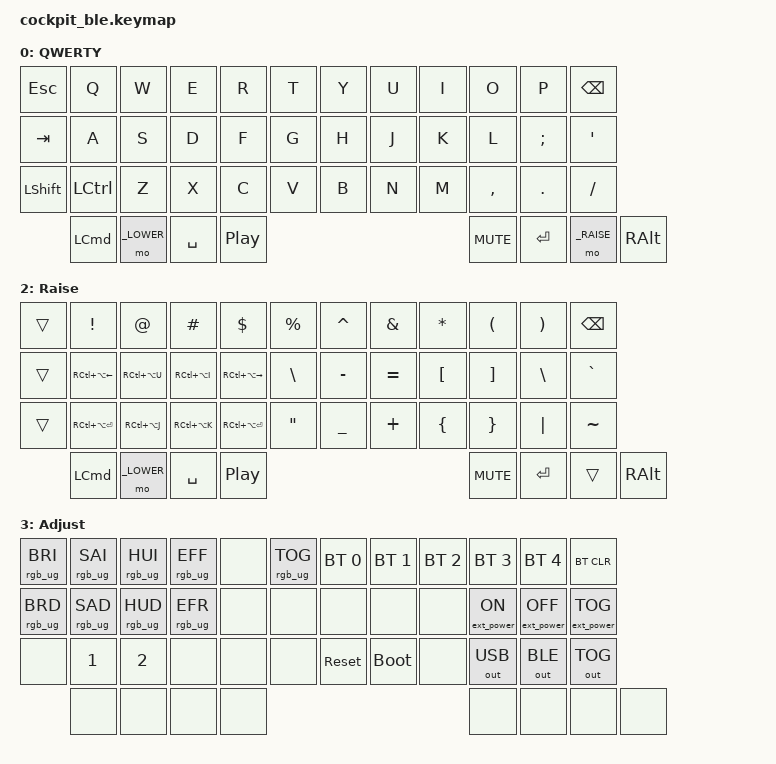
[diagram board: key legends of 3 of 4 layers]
/*
 * Copyright (c) 2023 ozkan (github.com/ozkan)
 *
 * SPDX-License-Identifier: MIT
 */

#include <behaviors.dtsi>
#include <dt-bindings/zmk/keys.h>
#include <dt-bindings/zmk/ext_power.h>
#include <dt-bindings/zmk/outputs.h>
#include <dt-bindings/zmk/bt.h>
#include <dt-bindings/zmk/rgb.h>


// Layers
#define _BASE          0
#define _LOWER         1
#define _RAISE         2
#define _ADJUST        3

// Using layer taps on thumbs, having quick tap as well helps w/ repeating space
&lt {
  quick_tap_ms = <200>;
};

&left_encoder {
     resolution = <4>; 
};
&right_encoder {
     resolution = <4>; 
};


/ {
    conditional_layers {
        compatible = "zmk,conditional-layers";
        tri_layer {
            if-layers = <_LOWER _RAISE>; // lower and raise
            then-layer = <_ADJUST>;      // adjust
        };
    };

    behaviors {
        ht: hold_tap {
            compatible = "zmk,behavior-hold-tap";
            #binding-cells = <2>;
            flavor = "tap-preferred";
            tapping-term-ms = <200>;
            quick-tap-ms = <150>;
            global-quick-tap;
            bindings = <&kp>, <&kp>;
        };
        rgb_encoder_right: rgb_encoder_right {
            compatible = "zmk,behavior-sensor-rotate";
            #sensor-binding-cells = <0>;
            bindings =  <&rgb_ug RGB_BRI>, <&rgb_ug RGB_BRD>;
        };
        rgb_encoder_left: rgb_encoder_left {
            compatible = "zmk,behavior-sensor-rotate";
            #sensor-binding-cells = <0>;
            bindings = <&rgb_ug RGB_EFF>, <&rgb_ug RGB_EFR>;
        };
    };

        combos {    
        compatible = "zmk,combos";
        
         studio_unlocking {
            timeout-ms = <50>;
            key-positions = <1 2>; 
            bindings = <&studio_unlock>; 
            layers = <_BASE>;     
        }; 

    };



    keymap {
        compatible = "zmk,keymap";
        default_layer {
       // ╭──────┬──────┬──────┬──────┬──────┬──────╮                          ╭──────┬──────┬──────┬──────┬──────┬──────╮
       // │  ESC │  Q   │  W   │  E   │  R   │  T   │                          │  Y   │  U   │  I   │  O   │  P   │ BSPC │
       // ├──────┼──────┼──────┼──────┼──────┼──────┤                          ├──────┼──────┼──────┼──────┼──────┼──────┤
       // │  TAB │  A   │  S   │  D   │  F   │  G   │                          │  H   │  J   │  K   │  L   │  ;   │  '   │
       // ├──────┼──────┼──────┼──────┼──────┼──────┤                          ├──────┼──────┼──────┼──────┼──────┼──────┤
       // │ SHFT │ CTRL │  Z   │  X   │  C   │  V   │         (ENCODERS)       │  B   │  N   │  M   │  ,   │  .   │  /   │
       // ╰──────┴──────┴──────┼──────┼──────┼──────┴─╮ ╭────────╮╭────────╮ ╭─┴──────┼──────┼──────┼──────┴──────┴──────╯
       //                      │  CMD │LOWER │ SPACE  │ │  PLAY  ││  MUTE  │ │  RET   │RAISE │ RALT │
       //                      ╰──────┴──────┴────────╯ ╰────────╯╰────────╯ ╰────────┴──────┴──────╯
            display-name = "QWERTY";
            bindings = <
                &kp ESC      &kp Q           &kp W   &kp E   &kp R   &kp T             &kp Y &kp U  &kp I    &kp O           &kp P           &kp BSPC
                &kp TAB      &kp A           &kp S   &kp D   &kp F   &kp G             &kp H &kp J  &kp K    &kp L           &kp SEMI        &kp SQT
                &kp LSHFT    &kp LCTRL       &kp Z   &kp X   &kp C   &kp V             &kp B &kp N  &kp M    &kp COMMA       &kp DOT         &kp FSLH
                                    &kp LCMD      &mo _LOWER      &kp SPACE         &kp C_PLAY_PAUSE  &kp C_MUTE       &kp RET     &mo _RAISE      &kp RALT
                                                         
            >;
            sensor-bindings = <&inc_dec_kp C_VOL_UP C_VOL_DN &inc_dec_kp RIGHT LEFT>;
        };

        lower_layer {
        // ╭──────┬──────┬──────┬──────┬──────┬──────╮                          ╭──────┬──────┬──────┬──────┬──────┬──────╮
        // │ ESC  │  1   │  2   │  3   │  4   │  5   │                          │  6   │  7   │  8   │  9   │  0   │ BSPC │
        // ├──────┼──────┼──────┼──────┼──────┼──────┤                          ├──────┼──────┼──────┼──────┼──────┼──────┤
        // │ TAB  │ C-UP │C-LEFT│C-RGHT│ LEFT │ RGHT │                          │ LEFT │ DOWN │  UP  │ RGHT │      │      │
        // ├──────┼──────┼──────┼──────┼──────┼──────┤                          ├──────┼──────┼──────┼──────┼──────┼──────┤
        // │ SHFT │  ~   │ NEXT │VOL_DN│VOL_UP│ PLAY │                          │ HOME │ END  │ PGUP │ PGDN │      │      │
        // ╰──────┴──────┴──────┼──────┼──────┼──────┴─╮ ╭────────╮╭────────╮ ╭─┴──────┼──────┼──────┼──────┴──────┴──────╯
        //                      │  CMD │      │  ALT   │ │        ││        │ │  RET   │RAISE │ RALT │
        //                      ╰──────┴──────┴────────╯ ╰────────╯╰────────╯ ╰────────┴──────┴──────╯
            display-name = "Lower";        
            bindings = <
                &kp ESC    &kp N1        &kp N2          &kp N3          &kp N4          &kp N5              &kp N6    &kp N7    &kp N8    &kp N9     &kp N0     &kp BSPC
                &kp TAB    &kp RC(UP)    &kp RC(LEFT)    &kp RC(RIGHT)   &kp LEFT        &kp RIGHT           &kp LEFT  &kp DOWN  &kp UP    &kp RIGHT  &trans     &trans
                &kp LSHFT  &kp TILDE     &kp C_NEXT      &kp C_VOL_DN    &kp C_VOL_UP    &kp C_PLAY_PAUSE    &kp HOME  &kp END   &kp PG_UP &kp PG_DN  &trans     &trans
                                          &kp LCMD      &trans      &kp LALT                     &kp RET     &mo _RAISE     &kp RALT
            >;
            
            
        };
        
        raise_layer {
        // ╭──────┬──────┬──────┬──────┬──────┬──────╮                          ╭──────┬──────┬──────┬──────┬──────┬──────╮
        // │      │  !   │  @   │  #   │  $   │  %   │                          │  ^   │  &   │  *   │  (   │  )   │ BSPC │
        // ├──────┼──────┼──────┼──────┼──────┼──────┤                          ├──────┼──────┼──────┼──────┼──────┼──────┤
        // │      │ RECT │ RECT │ RECT │ RECT │  \   │                          │  -   │  =   │  [   │  ]   │  \   │  `   │
        // ├──────┼──────┼──────┼──────┼──────┼──────┤                          ├──────┼──────┼──────┼──────┼──────┼──────┤
        // │      │ RECT │ RECT │ RECT │ RECT │  "   │                          │  _   │  +   │  {   │  }   │  |   │  ~   │
        // ╰──────┴──────┴──────┼──────┼──────┼──────┴─╮ ╭────────╮╭────────╮ ╭─┴──────┼──────┼──────┼──────┴──────┴──────╯
        //                      │  CMD │LOWER │ SPACE  │ │  PLAY  ││  MUTE  │ │  RET   │      │ RALT │
        //                      ╰──────┴──────┴────────╯ ╰────────╯╰────────╯ ╰────────┴──────┴──────╯
            display-name = "Raise";
            bindings = <
                &trans &kp EXCL              &kp AT          &kp HASH        &kp DLLR                &kp PRCNT  &kp CARET  &kp AMPS   &kp ASTRK   &kp LPAR    &kp RPAR   &kp BSPC
                &trans &kp RC(LA(LEFT))      &kp RC(LA(U))   &kp RC(LA(I))   &kp RC(LA(RIGHT))       &kp BSLH   &kp MINUS  &kp EQUAL  &kp LBKT    &kp RBKT    &kp BSLH   &kp GRAVE
                &trans &kp RC(LA(RET))       &kp RC(LA(J))   &kp RC(LA(K))   &kp RC(LA(RET))         &kp DQT    &kp UNDER  &kp PLUS   &kp LBRC    &kp RBRC    &kp PIPE   &kp TILDE
                                         &kp LCMD  &mo _LOWER &kp SPACE          &kp C_PLAY_PAUSE  &kp C_MUTE       &kp RET  &trans   &kp RALT
            >;

        };

        adjust_layer {
        // ╭──────┬──────┬──────┬──────┬──────┬──────╮                          ╭──────┬──────┬──────┬──────┬──────┬──────╮
        // │ BRI+ │ SAT+ │ HUE+ │ ANI+ │      │ TOG  │                          │  BT1 │ BT2  │ BT3  │ BT4  │ BT5  │BT_CLR│
        // ├──────┼──────┼──────┼──────┼──────┼──────┤                          ├──────┼──────┼──────┼──────┼──────┼──────┤
        // │ BRI- │ SAT- │ HUE- │ ANI- │      │      │                          │      │      │      │EP_ON │EP_OFF│EP_TOG│
        // ├──────┼──────┼──────┼──────┼──────┼──────┤                          ├──────┼──────┼──────┼──────┼──────┼──────┤
        // │      │      │      │      │      │      │                          │RESET │ BOOT │      │O_USB │O_BLE │OUTTOG│
        // ╰──────┴──────┴──────┼──────┼──────┼──────┴─╮ ╭────────╮╭────────╮ ╭─┴──────┼──────┼──────┼──────┴──────┴──────╯
        //                      │      │      │        │ │        ││        │ │        │      │      │
        //                      ╰──────┴──────┴────────╯ ╰────────╯╰────────╯ ╰────────┴──────┴──────╯
            display-name = "Adjust";        
            bindings = <
                &rgb_ug RGB_BRI &rgb_ug RGB_SAI &rgb_ug RGB_HUI &rgb_ug RGB_EFF &none &rgb_ug RGB_TOG            &bt BT_SEL 0 &bt BT_SEL 1  &bt BT_SEL 2 &bt BT_SEL 3       &bt BT_SEL 4        &bt BT_CLR
                &rgb_ug RGB_BRD &rgb_ug RGB_SAD &rgb_ug RGB_HUD &rgb_ug RGB_EFR &none         &none              &none        &none         &none        &ext_power EP_ON   &ext_power EP_OFF   &ext_power EP_TOG
                &none           &kp N1          &kp N2        &none           &none         &none              &sys_reset       &bootloader   &none        &out OUT_USB       &out OUT_BLE        &out OUT_TOG
                                                &none           &none           &none         &none      &none     &none        &none        &none
            >;
        };
    };
};






